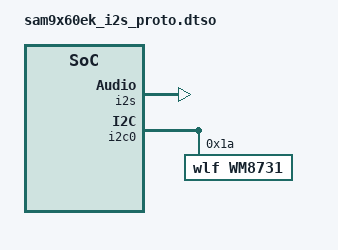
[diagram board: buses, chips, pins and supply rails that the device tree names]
// SPDX-License-Identifier: (GPL-2.0+ OR MIT)
/*
 * sam9x60-ek_i2s_proto.dtso - Device Tree file for SAM9x60-EK board
 * overlay blob for I2S with PROTO board. The blob uses i2s0 and i2c2 on flx4.
 *
 * Copyright (C) 2019 Microchip Technology, Inc.
 * Author: Codrin Ciubotariu <codrin.ciubotariu@microchip.com>
 *
 */
/dts-v1/;
/plugin/;

&i2s {
	status = "okay";
};

&i2c0 {
	#address-cells = <1>;
	#size-cells = <0>;
	wm8731: codec@1a {
		compatible = "wlf,wm8731";
		reg = <0x1a>;
	};
};

&{/} {
	sound {
		compatible = "mikroe,mikroe-proto";
		model = "wm8731 @ sam9x60ek";
		i2s-controller = <&i2s>;
		audio-codec = <&wm8731>;
		dai-format = "i2s";
        };
};

&qspi {
	status = "disabled";
};

